# FM33LG0XX register map
File version: 1.0
CPU: SC000 r1p0, little endian, no MPU, no FPU, 3 interrupt priority bits
Registers are 32-bit, read-write, reset 0x0 unless marked. A register's access mark holds for its fields unless they carry their own. Offsets are from the block's base; [hi:lo] are bit positions.

## DIVAS — DIVAS module information
Base 0x40019C00
0x00 OPRD — Operand Register
  [31:0] OPRD — OPRD field description
0x04 DIVSOR reset 0x1 — Divisor Regsiter
  [15:0] DIVSOR — DIVSOR field description
0x08 QUOT ro — Quotient Register
  [31:0] QUOT — QUOT field description
0x0C REMD ro — Reminder Register
  [15:0] REMD — REMD field description
0x10 ROOT ro
  [15:0] ROOT — ROOT field description
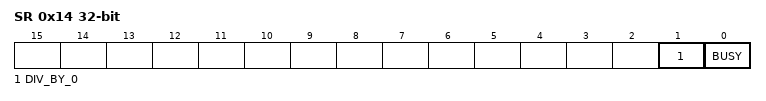
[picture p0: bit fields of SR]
0x14 SR ro — Status Register
  [1] DIV_BY_0 — DIV_BY_0 field description
  [0] BUSY — BUSY field description
0x18 CR — Control Register
  [0] MODE — MODE field description

## I2C — I2C module information
Base 0x40012400
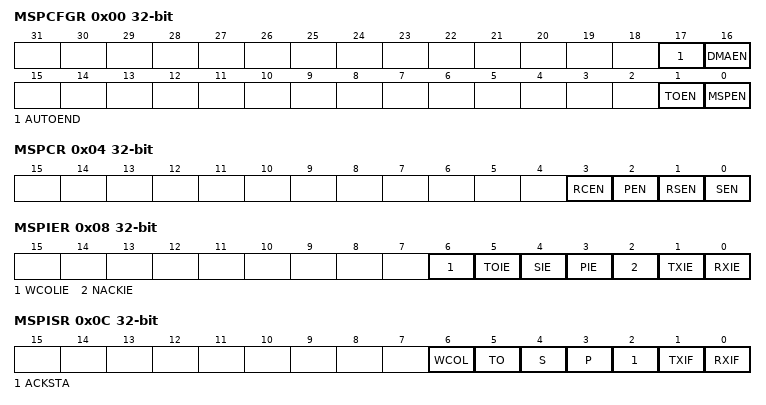
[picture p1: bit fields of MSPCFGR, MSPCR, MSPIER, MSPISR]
0x00 MSPCFGR — I2C Master Config Register
  [17] AUTOEND — AUTOEND field description
  [16] DMAEN — DMAEN field description
  [1] TOEN — TOEN field description
  [0] MSPEN — MSPEN field description
0x04 MSPCR — I2C Master Control Register
  [3] RCEN — RCEN field description
  [2] PEN — PEN field description
  [1] RSEN — RSEN field description
  [0] SEN — SEN field description
0x08 MSPIER — I2C Master Intterupt Enable Register
  [6] WCOLIE — WCOLIE field description
  [5] TOIE — TOIE field description
  [4] SIE — SIE field description
  [3] PIE — PIE field description
  [2] NACKIE — NACKIE field description
  [1] TXIE — TXIE field description
  [0] RXIE — RXIE field description
0x0C MSPISR access per field — I2C Master Interrupt Status Register
  [6] WCOL rw — WCOL field description
  [5] TO rw — TO field description
  [4] S ro — S field description
  [3] P ro — P field description
  [2] ACKSTA rw — ACKSTA field description
  [1] TXIF rw — TXIF field description
  [0] RXIF rw — RXIF field description
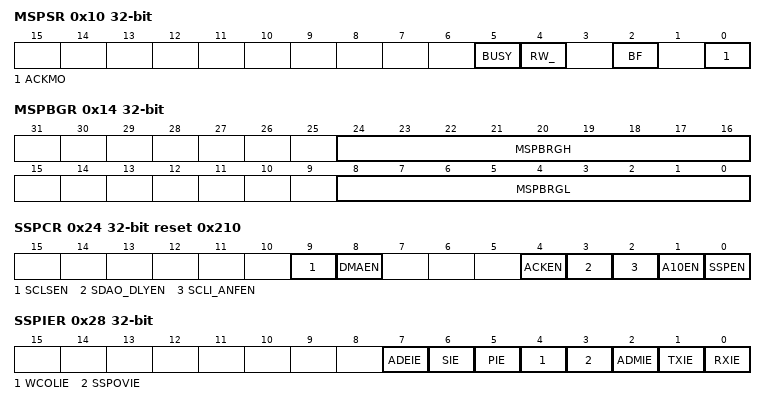
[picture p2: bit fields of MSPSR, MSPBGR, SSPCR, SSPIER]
0x10 MSPSR access per field — I2C Master Status Register
  [5] BUSY ro — BUSY field description
  [4] RW_ ro — RW_ field description
  [2] BF ro — BF field description
  [0] ACKMO rw — ACKMO field description
0x14 MSPBGR — I2C Master Baud rate Generator Register
  [24:16] MSPBRGH — MSPBRGH field description
  [8:0] MSPBRGL — MSPBRGL field description
0x18 MSPBUF — I2C Master transfer Buffer
  [7:0] MSPBUF — MSPBUF field description
0x1C MSPTCR — I2C Master Timing Control Register
  [8:0] SDAHD — SDAHD field description
0x20 MSPTOR reset 0xFFF — I2C Master Time-Out Register
  [11:0] TIMEOUT — TIMEOUT field description
0x24 SSPCR reset 0x210 — I2C Slave Control Register
  [9] SCLSEN — SCLSEN field description
  [8] DMAEN — DMAEN field description
  [4] ACKEN — ACKEN field description
  [3] SDAO_DLYEN — SDAO_DLYEN field description
  [2] SCLI_ANFEN — SCLI_ANFEN field description
  [1] A10EN — A10EN field description
  [0] SSPEN — SSPEN field description
0x28 SSPIER — I2C Slave Interrupt Enable Register
  [7] ADEIE — ADEIE field description
  [6] SIE — SIE field description
  [5] PIE — PIE field description
  [4] WCOLIE — WCOLIE field description
  [3] SSPOVIE — SSPOVIE field description
  [2] ADMIE — ADMIE field description
  [1] TXIE — TXIE field description
  [0] RXIE — RXIE field description
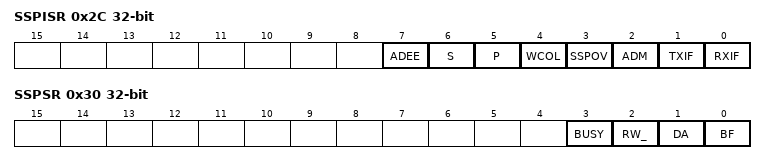
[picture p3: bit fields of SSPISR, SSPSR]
0x2C SSPISR access per field — I2C Slave Interrupt Status Register
  [7] ADEE rw — ADEE field description
  [6] S ro — S field description
  [5] P ro — P field description
  [4] WCOL rw — WCOL field description
  [3] SSPOV rw — SSPOV field description
  [2] ADM rw — ADM field description
  [1] TXIF rw — TXIF field description
  [0] RXIF rw — RXIF field description
0x30 SSPSR ro — I2C Slave Status Register
  [3] BUSY — BUSY field description
  [2] RW_ — RW_ field description
  [1] DA — DA field description
  [0] BF — BF field description
0x34 SSPBUF — I2C Slave transfer Buffer
  [7:0] SSPBUF — SSPBUF field description
0x38 SSPADR — I2C Slave Address Register
  [9:0] SSPADDR — SSPADDR field description
